# G32R501 register map
Vendor: Geehy Semiconductor Co., Ltd.; Series: G32R5; File version: 1.0
CPU: CM55 r0p1, little endian, MPU, FPU, double-precision FPU, DSP, VTOR, 4 interrupt priority bits
Registers are 32-bit, read-write, reset 0x0 unless marked. A register's access mark holds for its fields unless they carry their own. Offsets are from the block's base; [hi:lo] are bit positions.

## QEP1 — Quadrature Encoder Pulse
Base 0x40013800
Same registers: QEP2 0x40013C00
0x00 QPOSCNT — Position Counter
0x04 QPOSINIT — Position Counter Init
  [31:0] QPOSINIT — Position Counter initialize
0x08 QPOSMAX — Maximum Position Count
0x0C QPOSCMP — Position Compare
0x10 QPOSILAT ro — Index Position Latch
0x14 QPOSSLAT ro — Strobe Position Latch
0x18 QPOSLAT ro — Position Latch
0x1C QUTMR — QEP Unit Timer
0x20 QUPRD — QEP Unit Period
0x24 QWDTMR 16-bit — QEP Watchdog Timer
0x26 QWDPRD 16-bit — QEP Watchdog Period
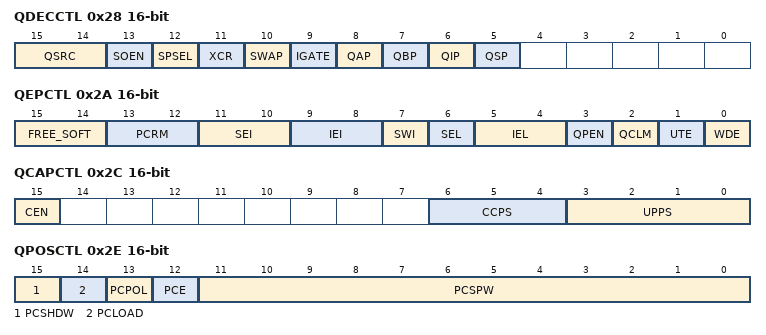
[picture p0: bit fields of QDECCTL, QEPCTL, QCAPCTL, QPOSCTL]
0x28 QDECCTL 16-bit — Quadrature Decoder Control
  [15:14] QSRC — Position-counter source selection
  [13] SOEN — Sync output-enable
  [12] SPSEL — Sync output pin selection
  [11] XCR — External Clock Rate
  [10] SWAP — CLK/DIR Signal Source for Position Counter
  [9] IGATE — Index pulse gating option
  [8] QAP — QEPA input polarity
  [7] QBP — QEPB input polarity
  [6] QIP — QEPI input polarity
  [5] QSP — QEPS input polarity
0x2A QEPCTL 16-bit — QEP Control
  [15:14] FREE_SOFT — Emulation mode
  [13:12] PCRM — Postion counter reset
  [11:10] SEI — Strobe event initialization of position counter
  [9:8] IEI — Index event init of position counter
  [7] SWI — Software init position counter
  [6] SEL — Strobe event latch of position counter
  [5:4] IEL — Index event latch of position counter
  [3] QPEN — Quadrature position counter enable/software reset
  [2] QCLM — QEP capture latch mode
  [1] UTE — QEP unit timer enable
  [0] WDE — QEP watchdog enable
0x2C QCAPCTL 16-bit — Qaudrature Capture Control
  [15] CEN — Enable QEP capture
  [6:4] CCPS — QEP capture timer clock prescaler
  [3:0] UPPS — Unit position event prescaler
0x2E QPOSCTL 16-bit — Position Compare Control
  [15] PCSHDW — Position compare of shadow enable
  [14] PCLOAD — Position compare of shadow load
  [13] PCPOL — Polarity of sync output
  [12] PCE — Position compare enable/disable
  [11:0] PCSPW — Select-position-compare sync output pulse width
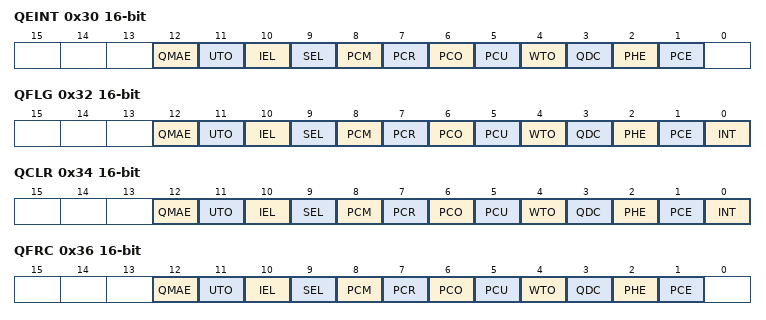
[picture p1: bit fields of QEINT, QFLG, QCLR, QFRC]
0x30 QEINT 16-bit — QEP Interrupt Control
  [12] QMAE — QMA Error Interrupt enable
  [11] UTO — Unit time out interrupt enable
  [10] IEL — Index event latch interrupt enable
  [9] SEL — Strobe event latch interrupt enable
  [8] PCM — Position-compare match interrupt enable
  [7] PCR — Position-compare ready interrupt enable
  [6] PCO — Position counter overflow interrupt enable
  [5] PCU — Position counter underflow interrupt enable
  [4] WTO — Watchdog time out interrupt enable
  [3] QDC — Quadrature direction change interrupt enable
  [2] PHE — Quadrature phase error interrupt enable
  [1] PCE — Position counter error interrupt enable
0x32 QFLG 16-bit ro — QEP Interrupt Flag
  [12] QMAE — QMA Error interrupt flag
  [11] UTO — Unit time out interrupt flag
  [10] IEL — Index event latch interrupt flag
  [9] SEL — Strobe event latch interrupt flag
  [8] PCM — Position-compare match interrupt flag
  [7] PCR — Position-compare ready interrupt flag
  [6] PCO — Position counter overflow interrupt flag
  [5] PCU — Position counter underflow interrupt flag
  [4] WTO — Watchdog time out interrupt flag
  [3] QDC — Quadrature direction change interrupt flag
  [2] PHE — Quadrature phase error interrupt flag
  [1] PCE — Position counter error interrupt flag
  [0] INT — Global interrupt status flag
0x34 QCLR 16-bit — QEP Interrupt Clear
  [12] QMAE — Clear QMA Error Interrupt flag
  [11] UTO — Clear Unit time out interrupt flag
  [10] IEL — Clear Index event latch interrupt flag
  [9] SEL — Clear Strobe event latch interrupt flag
  [8] PCM — Clear Position compare match interrupt flag
  [7] PCR — Clear Position compare ready interrupt flag
  [6] PCO — Clear Position counter overflow interrupt flag
  [5] PCU — Clear Position counter underflow interrupt flag
  [4] WTO — Clear Watchdog time out interrupt flag
  [3] QDC — Clear Quadrature direction change interrupt flag
  [2] PHE — Clear Quadrature phase error interrupt flag
  [1] PCE — Clear Position counter error interrupt flag
  [0] INT — Global interrupt status Clear flag
0x36 QFRC 16-bit — QEP Interrupt Force
  [12] QMAE — Force QMA error interrupt
  [11] UTO — Force unit time out interrupt
  [10] IEL — Force index event latch interrupt
  [9] SEL — Force strobe event latch interrupt
  [8] PCM — Force position-compare match interrupt
  [7] PCR — Force position-compare ready interrupt
  [6] PCO — Force position counter overflow interrupt
  [5] PCU — Force position counter underflow interrupt
  [4] WTO — Force watchdog time out interrupt
  [3] QDC — Force Quadrature direction change interrupt
  [2] PHE — Force Quadrature phase error interrupt
  [1] PCE — Force Position counter error interrupt
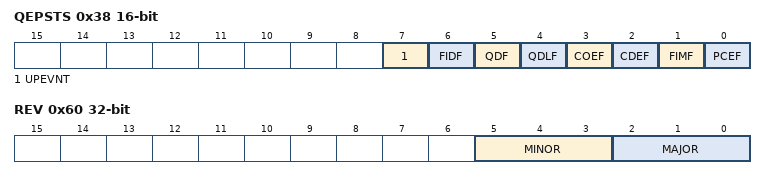
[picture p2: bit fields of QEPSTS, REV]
0x38 QEPSTS 16-bit — QEP Status
  [7] UPEVNT — Unit position event flag
  [6] FIDF ro — Direction on the first index marker
  [5] QDF ro — Quadrature direction flag
  [4] QDLF ro — QEP direction latch flag
  [3] COEF — Capture overflow error flag
  [2] CDEF — Capture direction error flag
  [1] FIMF — First index marker flag
  [0] PCEF ro — Position counter error flag
0x3A QCTMR 16-bit — QEP Capture Timer
  [15:0] QCTMR — Capture Timer
0x3C QCPRD 16-bit — QEP Capture Period
  [15:0] QCPRD — Capture Period
0x3E QCTMRLAT 16-bit ro — QEP Capture Latch
  [15:0] QCTMRLAT — Capture Timer latch
0x40 QCPRDLAT 16-bit ro — QEP Capture Period Latch
  [15:0] QCPRDLAT — Capture Period latch
0x60 REV ro — QEP Revision Number
  [5:3] MINOR — Minor Revision number
  [2:0] MAJOR — Major Revision number
0x64 QEPSTROBESEL — QEP Strobe select register
  [1:0] STROBESEL — Strobe source select
0x68 QMACTRL — QMA Control register
  [2:0] MODE — Select Mode for QMA mode
